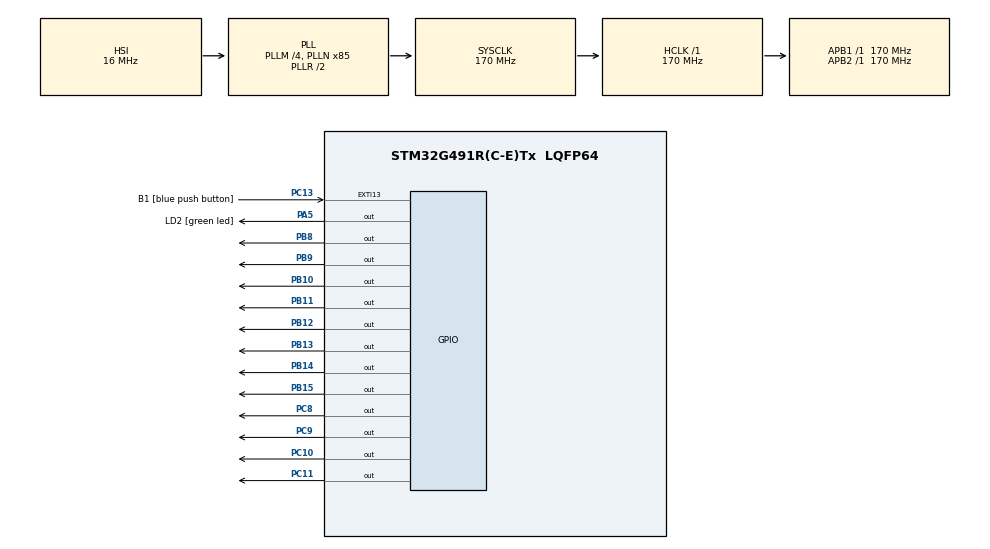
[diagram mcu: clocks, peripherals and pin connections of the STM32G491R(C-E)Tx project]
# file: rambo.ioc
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Mcu.Family=STM32G4
Mcu.Name=STM32G491R(C-E)Tx
Mcu.Package=LQFP64
NVIC.EXTI15_10_IRQn=true\:0\:0\:false\:false\:true\:true\:true\:true
NVIC.PriorityGroup=NVIC_PRIORITYGROUP_4
NVIC.TIM3_IRQn=true\:0\:0\:false\:false\:true\:true\:true\:true
NVIC.TIM4_IRQn=true\:0\:0\:false\:false\:true\:true\:true\:true
PA13.GPIO_Label=T_SWDIO
PA13.Signal=SYS_JTMS-SWDIO
PA14.GPIO_Label=T_SWCLK
PA14.Signal=SYS_JTCK-SWCLK
PA2.GPIO_Label=LPUART1_TX [STLINKV3E_VCP_RX]
PA2.Signal=LPUART1_TX
PA3.GPIO_Label=LPUART1_RX [STLINKV3E_VCP_TX]
PA3.Signal=LPUART1_RX
PA5.GPIO_Label=LD2 [green led]
PA5.Signal=GPIO_Output
PB10.Signal=GPIO_Output
PB11.Signal=GPIO_Output
PB12.Signal=GPIO_Output
PB13.Signal=GPIO_Output
PB14.Signal=GPIO_Output
PB15.Signal=GPIO_Output
PB3.GPIO_Label=T_SWO
PB3.Signal=SYS_JTDO-SWO
PB8-BOOT0.Signal=GPIO_Output
PB9.Signal=GPIO_Output
PC10.Signal=GPIO_Output
PC11.Signal=GPIO_Output
PC13.GPIO_Label=B1 [blue push button]
PC13.Signal=GPXTI13
PC14-OSC32_IN.GPIO_Label=RCC_OSC32_IN
PC14-OSC32_IN.Signal=RCC_OSC32_IN
PC15-OSC32_OUT.GPIO_Label=RCC_OSC32_OUT
PC15-OSC32_OUT.Signal=RCC_OSC32_OUT
PC8.Signal=GPIO_Output
PC9.Signal=GPIO_Output
PF0-OSC_IN.GPIO_Label=RCC_OSC_IN
PF0-OSC_IN.Signal=RCC_OSC_IN
PF1-OSC_OUT.GPIO_Label=RCC_OSC_OUT
PF1-OSC_OUT.Signal=RCC_OSC_OUT
ProjectManager.HeapSize=0x200
ProjectManager.StackSize=0x400
ProjectManager.TargetToolchain=STM32CubeIDE
RCC.ADC12Freq_Value=170000000
RCC.ADC345Freq_Value=170000000
RCC.AHBFreq_Value=170000000
RCC.APB1Freq_Value=170000000
RCC.APB1TimFreq_Value=170000000
RCC.APB2Freq_Value=170000000
RCC.APB2TimFreq_Value=170000000
RCC.CortexFreq_Value=170000000
RCC.EXTERNAL_CLOCK_VALUE=12288000
RCC.HCLKFreq_Value=170000000
RCC.HSE_VALUE=24000000
RCC.HSI48_VALUE=48000000
RCC.HSI_VALUE=16000000
RCC.LSE_VALUE=32768
RCC.PLLM=RCC_PLLM_DIV4
RCC.PLLN=85
RCC.RTCClockSelection=RCC_RTCCLKSOURCE_LSE
RCC.SYSCLKFreq_VALUE=170000000
RCC.SYSCLKSource=RCC_SYSCLKSOURCE_PLLCLK
RCC.USBFreq_Value=48000000
RCC.VCOOutputFreq_Value=340000000
TIM3.PeriodNoDither=10000-1
TIM3.Prescaler=170-1
TIM4.PeriodNoDither=1000-1
TIM4.Prescaler=170-1
VP_SYS_VS_DBSignals.Mode=DisableDeadBatterySignals
VP_TIM3_VS_ClockSourceINT.Mode=Internal
VP_TIM4_VS_ClockSourceINT.Mode=Internal
board=NUCLEO-G491RE

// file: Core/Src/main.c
/* USER CODE BEGIN Header */
/**
  ******************************************************************************
  * @file           : main.c
  * @brief          : Main program body
  ******************************************************************************
  * @attention
  *
  * Copyright (c) 2025 STMicroelectronics.
  * All rights reserved.
  *
  * This software is licensed under terms that can be found in the LICENSE file
  * in the root directory of this software component.
  * If no LICENSE file comes with this software, it is provided AS-IS.
  *
  ******************************************************************************
  */
/* USER CODE END Header */
#include "main.h"

/* USER CODE BEGIN Includes */
#include "display7seg.h"
#include "timers.h"
/* USER CODE END Includes */

TIM_HandleTypeDef htim3;
TIM_HandleTypeDef htim4;

void SystemClock_Config(void);
static void MX_GPIO_Init(void);
static void MX_TIM3_Init(void);
static void MX_TIM4_Init(void);

/* USER CODE BEGIN 0 */
void HAL_GPIO_EXTI_Callback(uint16_t GPIO_Pin){
	if(GPIOC -> IDR & 0x2000){//inverte estado de flag_count
		if(flag_count){
			flag_count=0;
		}
		else{
			flag_count=1;
		}
	}
}
/* USER CODE END 0 */

int main(void)
{

  /* MCU Configuration--------------------------------------------------------*/

  /* Reset of all peripherals, Initializes the Flash interface and the Systick. */
  HAL_Init();

  /* Configure the system clock */
  SystemClock_Config();

  /* Initialize all configured peripherals */
  MX_GPIO_Init();
  MX_TIM3_Init();
  MX_TIM4_Init();

  /* Infinite loop */
  /* USER CODE BEGIN WHILE */
  HAL_TIM_Base_Start_IT(&htim3);
  HAL_TIM_Base_Start_IT(&htim4);
  while (1)
  {
	  if(flag_7seg)
	  {
		  flag_7seg = 0;
		Atualiza7seg(contador7seg);
	  }
    /* USER CODE END WHILE */

  }
}

void SystemClock_Config(void)
{
  RCC_OscInitTypeDef RCC_OscInitStruct = {0};
  RCC_ClkInitTypeDef RCC_ClkInitStruct = {0};

  /** Configure the main internal regulator output voltage
  */
  HAL_PWREx_ControlVoltageScaling(PWR_REGULATOR_VOLTAGE_SCALE1_BOOST);

  /** Initializes the RCC Oscillators according to the specified parameters
  * in the RCC_OscInitTypeDef structure.
  */
  RCC_OscInitStruct.OscillatorType = RCC_OSCILLATORTYPE_HSI;
  RCC_OscInitStruct.HSIState = RCC_HSI_ON;
  RCC_OscInitStruct.HSICalibrationValue = RCC_HSICALIBRATION_DEFAULT;
  RCC_OscInitStruct.PLL.PLLState = RCC_PLL_ON;
  RCC_OscInitStruct.PLL.PLLSource = RCC_PLLSOURCE_HSI;
  RCC_OscInitStruct.PLL.PLLM = RCC_PLLM_DIV4;
  RCC_OscInitStruct.PLL.PLLN = 85;
  RCC_OscInitStruct.PLL.PLLP = RCC_PLLP_DIV2;
  RCC_OscInitStruct.PLL.PLLQ = RCC_PLLQ_DIV2;
  RCC_OscInitStruct.PLL.PLLR = RCC_PLLR_DIV2;
  if (HAL_RCC_OscConfig(&RCC_OscInitStruct) != HAL_OK)
  {
    Error_Handler();
  }

  /** Initializes the CPU, AHB and APB buses clocks
  */
  RCC_ClkInitStruct.ClockType = RCC_CLOCKTYPE_HCLK|RCC_CLOCKTYPE_SYSCLK
                              |RCC_CLOCKTYPE_PCLK1|RCC_CLOCKTYPE_PCLK2;
  RCC_ClkInitStruct.SYSCLKSource = RCC_SYSCLKSOURCE_PLLCLK;
  RCC_ClkInitStruct.AHBCLKDivider = RCC_SYSCLK_DIV1;
  RCC_ClkInitStruct.APB1CLKDivider = RCC_HCLK_DIV1;
  RCC_ClkInitStruct.APB2CLKDivider = RCC_HCLK_DIV1;

  if (HAL_RCC_ClockConfig(&RCC_ClkInitStruct, FLASH_LATENCY_4) != HAL_OK)
  {
    Error_Handler();
  }
}

static void MX_TIM3_Init(void)
{

  TIM_ClockConfigTypeDef sClockSourceConfig = {0};
  TIM_MasterConfigTypeDef sMasterConfig = {0};

  htim3.Instance = TIM3;
  htim3.Init.Prescaler = 170-1;
  htim3.Init.CounterMode = TIM_COUNTERMODE_UP;
  htim3.Init.Period = 9999;
  htim3.Init.ClockDivision = TIM_CLOCKDIVISION_DIV1;
  htim3.Init.AutoReloadPreload = TIM_AUTORELOAD_PRELOAD_DISABLE;
  if (HAL_TIM_Base_Init(&htim3) != HAL_OK)
  {
    Error_Handler();
  }
  sClockSourceConfig.ClockSource = TIM_CLOCKSOURCE_INTERNAL;
  if (HAL_TIM_ConfigClockSource(&htim3, &sClockSourceConfig) != HAL_OK)
  {
    Error_Handler();
  }
  sMasterConfig.MasterOutputTrigger = TIM_TRGO_RESET;
  sMasterConfig.MasterSlaveMode = TIM_MASTERSLAVEMODE_DISABLE;
  if (HAL_TIMEx_MasterConfigSynchronization(&htim3, &sMasterConfig) != HAL_OK)
  {
    Error_Handler();
  }

}

static void MX_TIM4_Init(void)
{

  TIM_ClockConfigTypeDef sClockSourceConfig = {0};
  TIM_MasterConfigTypeDef sMasterConfig = {0};

  htim4.Instance = TIM4;
  htim4.Init.Prescaler = 170-1;
  htim4.Init.CounterMode = TIM_COUNTERMODE_UP;
  htim4.Init.Period = 999;
  htim4.Init.ClockDivision = TIM_CLOCKDIVISION_DIV1;
  htim4.Init.AutoReloadPreload = TIM_AUTORELOAD_PRELOAD_DISABLE;
  if (HAL_TIM_Base_Init(&htim4) != HAL_OK)
  {
    Error_Handler();
  }
  sClockSourceConfig.ClockSource = TIM_CLOCKSOURCE_INTERNAL;
  if (HAL_TIM_ConfigClockSource(&htim4, &sClockSourceConfig) != HAL_OK)
  {
    Error_Handler();
  }
  sMasterConfig.MasterOutputTrigger = TIM_TRGO_RESET;
  sMasterConfig.MasterSlaveMode = TIM_MASTERSLAVEMODE_DISABLE;
  if (HAL_TIMEx_MasterConfigSynchronization(&htim4, &sMasterConfig) != HAL_OK)
  {
    Error_Handler();
  }

}

static void MX_GPIO_Init(void)
{
  GPIO_InitTypeDef GPIO_InitStruct = {0};

  /* GPIO Ports Clock Enable */
  __HAL_RCC_GPIOC_CLK_ENABLE();
  __HAL_RCC_GPIOF_CLK_ENABLE();
  __HAL_RCC_GPIOA_CLK_ENABLE();
  __HAL_RCC_GPIOB_CLK_ENABLE();

  /*Configure GPIO pin Output Level */
  HAL_GPIO_WritePin(LD2_GPIO_Port, LD2_Pin, GPIO_PIN_RESET);

  /*Configure GPIO pin Output Level */
  HAL_GPIO_WritePin(GPIOB, GPIO_PIN_10|GPIO_PIN_11|GPIO_PIN_12|GPIO_PIN_13
                          |GPIO_PIN_14|GPIO_PIN_15|GPIO_PIN_8|GPIO_PIN_9, GPIO_PIN_RESET);

  /*Configure GPIO pin Output Level */
  HAL_GPIO_WritePin(GPIOC, GPIO_PIN_8|GPIO_PIN_9|GPIO_PIN_10|GPIO_PIN_11, GPIO_PIN_RESET);

  /*Configure GPIO pin : B1_Pin */
  GPIO_InitStruct.Pin = B1_Pin;
  GPIO_InitStruct.Mode = GPIO_MODE_IT_RISING;
  GPIO_InitStruct.Pull = GPIO_NOPULL;
  HAL_GPIO_Init(B1_GPIO_Port, &GPIO_InitStruct);

  /*Configure GPIO pins : LPUART1_TX_Pin LPUART1_RX_Pin */
  GPIO_InitStruct.Pin = LPUART1_TX_Pin|LPUART1_RX_Pin;
  GPIO_InitStruct.Mode = GPIO_MODE_AF_PP;
  GPIO_InitStruct.Pull = GPIO_NOPULL;
  GPIO_InitStruct.Speed = GPIO_SPEED_FREQ_LOW;
  GPIO_InitStruct.Alternate = GPIO_AF12_LPUART1;
  HAL_GPIO_Init(GPIOA, &GPIO_InitStruct);

  /*Configure GPIO pin : LD2_Pin */
  GPIO_InitStruct.Pin = LD2_Pin;
  GPIO_InitStruct.Mode = GPIO_MODE_OUTPUT_PP;
  GPIO_InitStruct.Pull = GPIO_NOPULL;
  GPIO_InitStruct.Speed = GPIO_SPEED_FREQ_LOW;
  HAL_GPIO_Init(LD2_GPIO_Port, &GPIO_InitStruct);

  /*Configure GPIO pins : PB10 PB11 PB12 PB13
                           PB14 PB15 PB8 PB9 */
  GPIO_InitStruct.Pin = GPIO_PIN_10|GPIO_PIN_11|GPIO_PIN_12|GPIO_PIN_13
                          |GPIO_PIN_14|GPIO_PIN_15|GPIO_PIN_8|GPIO_PIN_9;
  GPIO_InitStruct.Mode = GPIO_MODE_OUTPUT_PP;
  GPIO_InitStruct.Pull = GPIO_NOPULL;
  GPIO_InitStruct.Speed = GPIO_SPEED_FREQ_LOW;
  HAL_GPIO_Init(GPIOB, &GPIO_InitStruct);

  /*Configure GPIO pins : PC8 PC9 PC10 PC11 */
  GPIO_InitStruct.Pin = GPIO_PIN_8|GPIO_PIN_9|GPIO_PIN_10|GPIO_PIN_11;
  GPIO_InitStruct.Mode = GPIO_MODE_OUTPUT_PP;
  GPIO_InitStruct.Pull = GPIO_NOPULL;
  GPIO_InitStruct.Speed = GPIO_SPEED_FREQ_LOW;
  HAL_GPIO_Init(GPIOC, &GPIO_InitStruct);

  /* EXTI interrupt init*/
  HAL_NVIC_SetPriority(EXTI15_10_IRQn, 0, 0);
  HAL_NVIC_EnableIRQ(EXTI15_10_IRQn);

}

void Error_Handler(void)
{
  __disable_irq();
  while (1)
  {
  }
}
